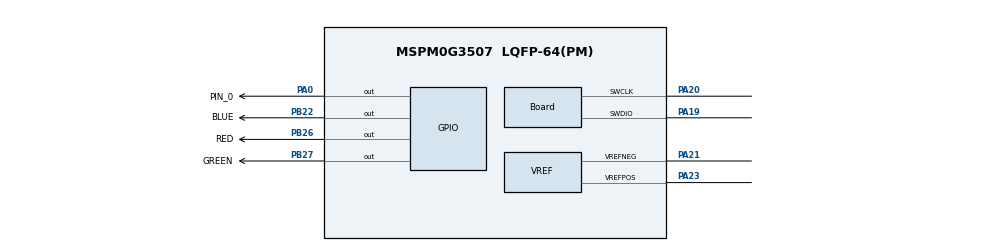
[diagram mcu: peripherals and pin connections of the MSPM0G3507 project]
//@cliArgs --device "MSPM0G350X" --package "LQFP-64(PM)" --part "Default"
//@v2CliArgs --device "MSPM0G3507" --package "LQFP-64(PM)"
// @cliArgs --board /ti/boards/LP_MSPM0G3507 --rtos nortos

/**
 * Import the modules used in this configuration.
 */
const ADC12         = scripting.addModule("/ti/driverlib/ADC12", {}, false);
const ADC121        = ADC12.addInstance();
const Board         = scripting.addModule("/ti/driverlib/Board");
const GPIO          = scripting.addModule("/ti/driverlib/GPIO", {}, false);
const GPIO1         = GPIO.addInstance();
const SYSCTL        = scripting.addModule("/ti/driverlib/SYSCTL");
const TIMER         = scripting.addModule("/ti/driverlib/TIMER", {}, false);
const TIMER1        = TIMER.addInstance();
const VREF          = scripting.addModule("/ti/driverlib/VREF");
const ProjectConfig = scripting.addModule("/ti/project_config/ProjectConfig");

/**
 * Write custom configuration values to the imported modules.
 */
ADC121.$name                      = "ADC12_0";
ADC121.repeatMode                 = true;
ADC121.resolution                 = "DL_ADC12_SAMP_CONV_RES_8_BIT";
ADC121.sampClkDiv                 = "DL_ADC12_CLOCK_DIVIDE_16";
ADC121.enabledInterrupts          = ["DL_ADC12_INTERRUPT_MEM0_RESULT_LOADED"];
ADC121.subChanID                  = 1;
ADC121.sampleTime0                = "40 us";
ADC121.adcMem0chansel             = "DL_ADC12_INPUT_CHAN_2";
ADC121.trigSrc                    = "DL_ADC12_TRIG_SRC_EVENT";
ADC121.adcMem0trig                = "DL_ADC12_TRIGGER_MODE_TRIGGER_NEXT";
ADC121.peripheral.$assign         = "ADC0";
ADC121.peripheral.adcPin2.$assign = "PA25";
ADC121.adcPin2Config.$name        = "ti_driverlib_gpio_GPIOPinGeneric0";

Board.peripheral.$assign          = "DEBUGSS";
Board.peripheral.swclkPin.$assign = "PA20";
Board.peripheral.swdioPin.$assign = "PA19";

GPIO1.$name                               = "LED";
GPIO1.associatedPins.create(4);
GPIO1.associatedPins[0].launchPadShortcut = "LED2RedEn";
GPIO1.associatedPins[0].$name             = "RED";
GPIO1.associatedPins[0].pin.$assign       = "PB26";
GPIO1.associatedPins[1].launchPadShortcut = "LED2BlueEn";
GPIO1.associatedPins[1].$name             = "BLUE";
GPIO1.associatedPins[1].pin.$assign       = "PB22";
GPIO1.associatedPins[2].$name             = "GREEN";
GPIO1.associatedPins[2].launchPadShortcut = "LED2GreenEn";
GPIO1.associatedPins[2].pin.$assign       = "PB27";
GPIO1.associatedPins[3].$name             = "PIN_0";
GPIO1.associatedPins[3].pin.$assign       = "PA0";

SYSCTL.forceDefaultClkConfig = true;
SYSCTL.clockTreeEn           = true;

TIMER1.$name                       = "SAMPLING_TIMER";
TIMER1.timerClkPrescale            = 8;
TIMER1.timerMode                   = "PERIODIC";
TIMER1.timerClkDiv                 = 8;
TIMER1.event1PublisherChannel      = 1;
TIMER1.event1ControllerInterruptEn = ["ZERO_EVENT"];
TIMER1.timerPeriod                 = "33 ms";
TIMER1.peripheral.$assign          = "TIMA0";

VREF.basicVrefPins                 = "VREF+-";
VREF.basicExtVolt                  = 3.3;
VREF.basicMode                     = "DL_VREF_ENABLE_DISABLE";
VREF.peripheral.$assign            = "VREF";
VREF.peripheral.vrefPosPin.$assign = "PA23";
VREF.peripheral.vrefNegPin.$assign = "PA21";

ProjectConfig.genLibCMSIS        = true;
ProjectConfig.migrationCondition = true;
